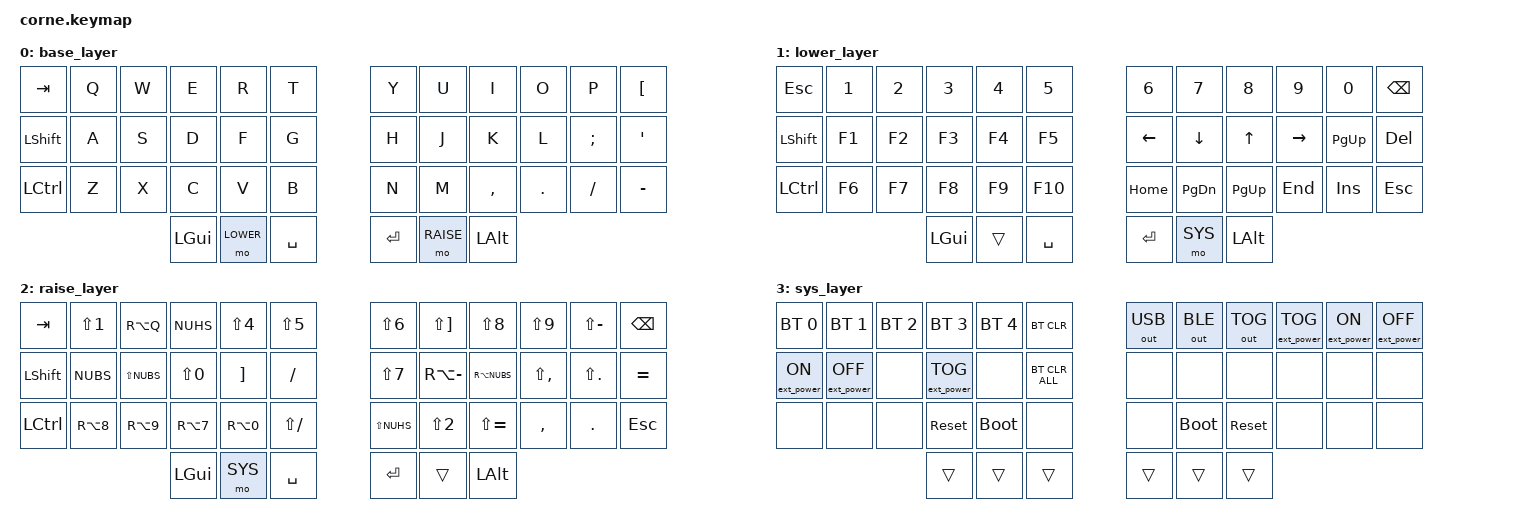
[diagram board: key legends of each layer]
/*
 * Corne v3 42-key starter keymap for Tom.
 *
 * v4 changes:
 * - LOWER: swapped DEL and BSPC so BSPC matches the same physical key as RAISE.
 * - RAISE: changed the key below BSPC from grave (`) to acute accent (´).
 * - SYS: added external-power toggle for OLED/peripheral power saving.
 *   Note: on nice!nano this may also switch other peripherals on the same power rail.
 *
 * Geometry:
 * - 3 rows x 12 keys + 6 thumb keys = 42 bindings per layer.
 *
 * Host OS layout assumption:
 * - German / QWERTZ.
 * - ZMK keycodes are HID/US-position keycodes:
 *   &kp Y outputs German "Z"; &kp Z outputs German "Y".
 */

#include <behaviors.dtsi>
#include <dt-bindings/zmk/keys.h>
#include <dt-bindings/zmk/bt.h>
#include <dt-bindings/zmk/outputs.h>
#include <dt-bindings/zmk/ext_power.h>

#define BASE  0
#define LOWER 1
#define RAISE 2
#define SYS   3

&led_strip {
  chain-length = <27>;
  // 21 backlight + 6 glowlight
};

/ {
        keymap {
                compatible = "zmk,keymap";

                base_layer {
// -----------------------------------------------------------------------------------------
// German output with German OS layout:
// |  TAB |  Q  |  W  |  E  |  R  |  T  |   |  Z  |  U  |  I  |  O  |  P  |  Ü  |
// | SHFT |  A  |  S  |  D  |  F  |  G  |   |  H  |  J  |  K  |  L  |  Ö  |  Ä  |
// | CTRL |  Y  |  X  |  C  |  V  |  B  |   |  N  |  M  |  ,  |  .  |  -  |  ß  |
//                    | GUI | LWR | SPC |   | ENT | RSE | ALT |
                        bindings = <
   &kp TAB   &kp Q &kp W &kp E &kp R &kp T   &kp Y &kp U  &kp I     &kp O   &kp P    &kp LBKT
   &kp LSHFT &kp A &kp S &kp D &kp F &kp G   &kp H &kp J  &kp K     &kp L   &kp SEMI &kp SQT
   &kp LCTRL &kp Z &kp X &kp C &kp V &kp B   &kp N &kp M  &kp COMMA &kp DOT &kp FSLH &kp MINUS
                  &kp LGUI &mo LOWER &kp SPACE   &kp RET &mo RAISE &kp LALT
                        >;
                };

                lower_layer {
// -----------------------------------------------------------------------------------------
// | ESC  |  1  |  2  |  3  |  4  |  5  |   |  6  |  7  |  8  |  9  |  0  | BSPC |
// | SHFT | F1  | F2  | F3  | F4  | F5  |   | LFT | DWN | UP  | RGT | PGU | DEL  |
// | CTRL | F6  | F7  | F8  | F9  | F10 |   | HOM | PGD | PGU | END | INS | ESC  |
//                    | GUI |     | SPC |   | ENT | SYS | ALT |
                        bindings = <
   &kp ESC   &kp N1  &kp N2  &kp N3  &kp N4  &kp N5     &kp N6   &kp N7   &kp N8    &kp N9    &kp N0    &kp BSPC
   &kp LSHFT &kp F1  &kp F2  &kp F3  &kp F4  &kp F5     &kp LEFT &kp DOWN &kp UP    &kp RIGHT &kp PG_UP &kp DEL
   &kp LCTRL &kp F6  &kp F7  &kp F8  &kp F9  &kp F10    &kp HOME &kp PG_DN &kp PG_UP &kp END   &kp INS   &kp ESC
                  &kp LGUI &trans &kp SPACE   &kp RET &mo SYS &kp LALT
                        >;
                };

                raise_layer {
// -----------------------------------------------------------------------------------------
// Programming symbols for German OS layout.
// Some symbols are sent via German AltGr combinations using RALT, written as RA(...).
//
// Intended output:
// | TAB |  !  |  @  |  #  |  $  |  %  |   |  &  |  *  |  (  |  )  |  ?  | BSPC |
// | SHFT|  <  |  >  |  =  |  +  |  -  |   |  /  |  \  |  |  |  ;  |  :  |  ´   |
// | CTRL|  [  |  ]  |  {  |  }  |  _  |   |  '  |  "  |  `  |  ,  |  .  | ESC  |
//                    | GUI | SYS | SPC |   | ENT |     | ALT |
                        bindings = <
   &kp TAB   &kp LS(N1)   &kp RA(Q)    &kp NUHS     &kp LS(N4)   &kp LS(N5)     &kp LS(N6)   &kp LS(RBKT) &kp LS(N8)    &kp LS(N9)   &kp LS(MINUS) &kp BSPC
   &kp LSHFT &kp NUBS     &kp LS(NUBS) &kp LS(N0)   &kp RBKT     &kp FSLH       &kp LS(N7)   &kp RA(MINUS)&kp RA(NUBS)  &kp LS(COMMA)&kp LS(DOT)   &kp EQUAL
   &kp LCTRL &kp RA(N8)   &kp RA(N9)   &kp RA(N7)   &kp RA(N0)   &kp LS(FSLH)   &kp LS(NUHS) &kp LS(N2)   &kp LS(EQUAL) &kp COMMA    &kp DOT       &kp ESC
                       &kp LGUI &mo SYS &kp SPACE   &kp RET &trans &kp LALT
                        >;
                };

                sys_layer {
// -----------------------------------------------------------------------------------------
// | BT0  | BT1  | BT2  | BT3  | BT4  | BTCLR |   | USB | BLE | OUT | PWR |     |     |
// |      |      |      |      | PWR  |       |   |     |     |     |     |     |     |
// |      |      |      | RST  | BOOT |       |   |     | BOOT| RST |     |     |     |
//                    |     |     |     |   |     |     |     |
                        bindings = <
   &bt BT_SEL 0 &bt BT_SEL 1 &bt BT_SEL 2 &bt BT_SEL 3 &bt BT_SEL 4 &bt BT_CLR     &out OUT_USB &out OUT_BLE &out OUT_TOG &ext_power EP_TOG &ext_power EP_ON &ext_power EP_OFF
   &ext_power EP_ON       &ext_power EP_OFF       &none        &ext_power EP_TOG        &none        &bt BT_CLR_ALL &none        &none        &none        &none       &none       &none
   &none        &none        &none        &sys_reset   &bootloader  &none          &none        &bootloader  &sys_reset   &none       &none       &none
                       &trans &trans &trans   &trans &trans &trans
                        >;
                };
        };
};
